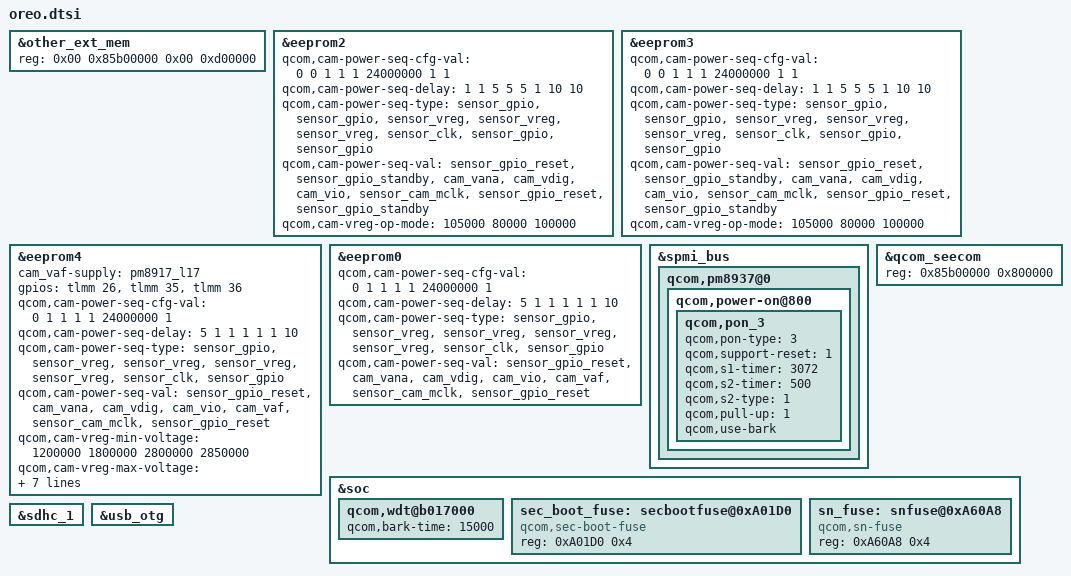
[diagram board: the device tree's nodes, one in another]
/* From compare result of Nougat dtb and Oreo dtb */
&other_ext_mem {
	reg = <0x00 0x85b00000 0x00 0xd00000>;
};

&eeprom2 {
	qcom,cam-power-seq-cfg-val = <0 0 1 1 1 24000000 1 1>;
	qcom,cam-power-seq-delay = <1 1 5 5 5 1 10 10>;
	qcom,cam-power-seq-type =
		"sensor_gpio",
		"sensor_gpio",
		"sensor_vreg",
		"sensor_vreg",
		"sensor_vreg",
		"sensor_clk",
		"sensor_gpio",
		"sensor_gpio";
	qcom,cam-power-seq-val =
		"sensor_gpio_reset",
		"sensor_gpio_standby",
		"cam_vana",
		"cam_vdig",
		"cam_vio",
		"sensor_cam_mclk",
		"sensor_gpio_reset",
		"sensor_gpio_standby";
	qcom,cam-vreg-op-mode = <105000 80000 100000>;
};

&eeprom3 {
	qcom,cam-power-seq-cfg-val = <0 0 1 1 1 24000000 1 1>;
	qcom,cam-power-seq-delay = <1 1 5 5 5 1 10 10>;
	qcom,cam-power-seq-type =
		"sensor_gpio",
		"sensor_gpio",
		"sensor_vreg",
		"sensor_vreg",
		"sensor_vreg",
		"sensor_clk",
		"sensor_gpio",
		"sensor_gpio";
	qcom,cam-power-seq-val =
		"sensor_gpio_reset",
		"sensor_gpio_standby",
		"cam_vana",
		"cam_vdig",
		"cam_vio",
		"sensor_cam_mclk",
		"sensor_gpio_reset",
		"sensor_gpio_standby";
	qcom,cam-vreg-op-mode = <105000 80000 100000>;
};

&eeprom4 {
	cam_vaf-supply = <&pm8917_l17>;
	gpios = <&tlmm 26 0>,
		<&tlmm 35 0>,
		<&tlmm 36 0>;
	qcom,cam-power-seq-cfg-val = <0 1 1 1 1 24000000 1>;
	qcom,cam-power-seq-delay = <5 1 1 1 1 1 10>;
	qcom,cam-power-seq-type =
		"sensor_gpio",
		"sensor_vreg",
		"sensor_vreg",
		"sensor_vreg",
		"sensor_vreg",
		"sensor_clk",
		"sensor_gpio";
	qcom,cam-power-seq-val =
		"sensor_gpio_reset",
		"cam_vana",
		"cam_vdig",
		"cam_vio",
		"cam_vaf",
		"sensor_cam_mclk",
		"sensor_gpio_reset";
	qcom,cam-vreg-min-voltage = <1200000 1800000 2800000 2850000>;
	qcom,cam-vreg-max-voltage = <1200000 1800000 2800000 2850000>;
	qcom,cam-vreg-name = "cam_vdig", "cam_vio", "cam_vana",
						"cam_vaf";
	qcom,cam-vreg-op-mode = <200000 80000 100000 100000>;
	qcom,gpio-req-tbl-label = "CAMIF_MCLK0",
					"CAM_RESET0",
					"CAM_STANDBY0";
};

&eeprom0 {
	qcom,cam-power-seq-cfg-val = <0 1 1 1 1 24000000 1>;
	qcom,cam-power-seq-delay = <5 1 1 1 1 1 10>;
	qcom,cam-power-seq-type =
		"sensor_gpio",
		"sensor_vreg",
		"sensor_vreg",
		"sensor_vreg",
		"sensor_vreg",
		"sensor_clk",
		"sensor_gpio";
	qcom,cam-power-seq-val =
		"sensor_gpio_reset",
		"cam_vana",
		"cam_vdig",
		"cam_vio",
		"cam_vaf",
		"sensor_cam_mclk",
		"sensor_gpio_reset";
};

&spmi_bus {
	qcom,pm8937@0 {
		qcom,power-on@800 {
			qcom,pon_3 {
				qcom,pon-type = <3>;
				qcom,support-reset = <1>;
				qcom,s1-timer = <3072>;
				qcom,s2-timer = <500>;
				qcom,s2-type = <1>;
				qcom,pull-up = <1>;
				qcom,use-bark;
			};
		};
	};
};

&qcom_seecom {
	reg = <0x85b00000 0x800000>;
};

&soc {
	qcom,wdt@b017000 {
		qcom,bark-time = <15000>;
	};
};

&sdhc_1 {
	/delete-property/ qcom,vdd-always-on;
};

&soc {
	/* WARNING: Redefine node */
	/delete-node/ secbootfuse@0xa41d0;
	sec_boot_fuse: secbootfuse@0xA01D0 {
		compatible = "qcom,sec-boot-fuse";
		reg = <0xA01D0 0x4>;
		reg-names = "sec-boot-base";
	};

	/* WARNING: Redefine node */
	/delete-node/ snfuse@0xa0128;
	sn_fuse: snfuse@0xA60A8 {
		compatible = "qcom,sn-fuse";
		reg = <0xA60A8 0x4>;
		reg-names = "sn-base";
	};
};

&usb_otg {
	/delete-property/ qcom,hsusb-otg-default-mode;
};
